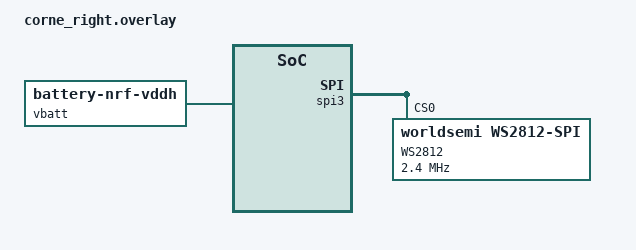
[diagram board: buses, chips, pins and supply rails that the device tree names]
/*
 * Copyright (c) 2020 Pete Johanson
 *
 * SPDX-License-Identifier: MIT
 */

#include "corne.dtsi"

&default_transform {
	col-offset = <6>;
};

&kscan0 {
    col-gpios
        = <&pro_micro 14  GPIO_ACTIVE_HIGH>
        , <&pro_micro 15  GPIO_ACTIVE_HIGH>
        , <&pro_micro 18  GPIO_ACTIVE_HIGH>
        , <&pro_micro 19  GPIO_ACTIVE_HIGH>
        , <&pro_micro 20  GPIO_ACTIVE_HIGH>
        , <&pro_micro 21  GPIO_ACTIVE_HIGH>
        ;
};
/ {
    chosen {
      zmk,battery = &vbatt;
    };

    vbatt: vbatt {
        compatible = "zmk,battery-nrf-vddh";
    };
};

&spi3 {
    compatible = "nordic,nrf-spim";
    status = "okay";
    pinctrl-0 = <&spi3_default>;
    pinctrl-1 = <&spi3_sleep>;
    pinctrl-names = "default", "sleep";

    led_strip: ws2812@0 {
        compatible = "worldsemi,ws2812-spi";
        label = "WS2812";
        reg = <0>;
        spi-max-frequency = <2400000>;
        chain-length = <27>;   /* 21 frontales + 6 traseros */
        spi-one-frame = <0x70>;
        spi-zero-frame = <0x40>;
        color-mapping = <LED_COLOR_ID_GREEN LED_COLOR_ID_RED LED_COLOR_ID_BLUE>;
    };
};

&zmk_underglow {
    compatible = "zmk,underglow";
    strip = <&led_strip>;
    pixel-count = <27>;
};
